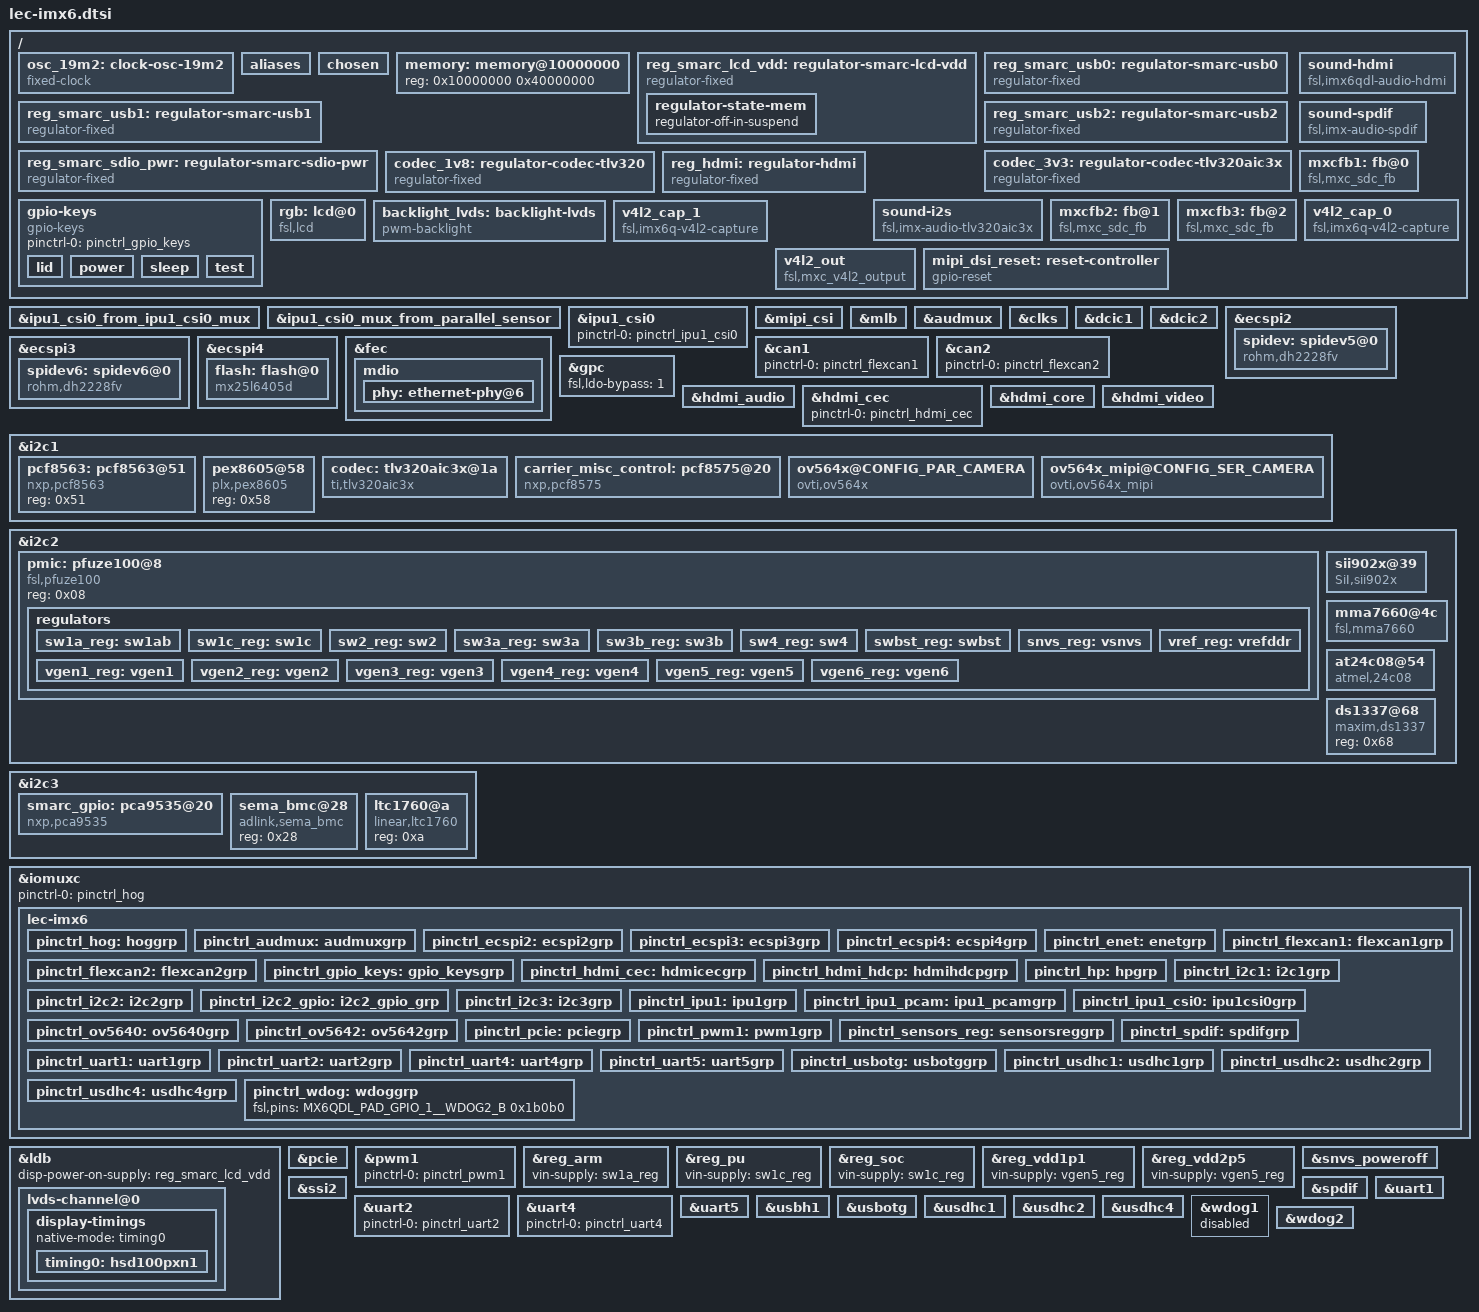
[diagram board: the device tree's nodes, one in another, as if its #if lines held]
// SPDX-License-Identifier: GPL-2.0+
//
// Copyright 2014-2016 LiPPERT ADLINK Technology GmbH
// Copyright 2012 Freescale Semiconductor, Inc.
// Copyright 2011 Linaro Ltd.

/* On-module multiplexer: 0 enables SMARC SPI0, !=0 enables I2S0 instead:
 * 1=TI TLV320AIC23 on LEC-Base R1 carrier, 2=Freescale SGTL5000 on LEC-Base R2 */
#define CONFIG_I2S_AUDIO       1
//#define CONFIG_I2S_AUDIO       2

/* The LEC-Base carrier doesn't include cameras, but allows connecting some. */
#define CONFIG_SER_CAMERA      3c /* I2C addr of serial camera, hex without "0x" */
//#define CONFIG_PAR_CAMERA    3c /* I2C addr of parallel camera */


/* Freescale defines 2 alternative DT nodes for the VPU: The one normally active
 * loads a driver called 'mxc_vpu'. The other, disabled one, would invoke a
 * different driver named 'coda'. None of Freescale's sample dts files enable it, 
 * but the code is there, appearently dormant, in imx6qdl.dtsi. 
*/
#define VPU_CODA       0

#include <dt-bindings/clock/imx6qdl-clock.h>
#include <dt-bindings/gpio/gpio.h>
#include <dt-bindings/input/input.h>

#define __0x(X) 0x##X  /* prefix hex digits with "0x" */
#define _0x(X) __0x(X)


/ {
	osc_19m2: clock-osc-19m2 {
        compatible = "fixed-clock";
        #clock-cells = <0>;
        clock-frequency = <19200000>;
        clock-output-names = "osc_19m2";
    };
	aliases {
		mxcfb0 = &mxcfb1;
		mxcfb1 = &mxcfb2;
		mxcfb2 = &mxcfb3;
	};

	chosen {
		/* U-Boot provides this via "console=..." in the 'params' variable. */
		//stdout-path = &uart1;
	};

	memory: memory@10000000 {
		device_type = "memory";
		reg = <0x10000000 0x40000000>;	/* dummy size, overwritten by U-Boot */
	};

	reg_smarc_lcd_vdd: regulator-smarc-lcd-vdd {
		compatible = "regulator-fixed";
		regulator-name = "smarc_lcd_vdd";
		gpio = <&gpio1 30 GPIO_ACTIVE_HIGH>; /* SMARC LCD_VDD_EN */
		enable-active-high;
		regulator-always-on; /* Freescale's fb/lcd/ldb drivers can't control a regulator yet :-( */
		regulator-state-mem { regulator-off-in-suspend; }; /* no effect? */
	};

	reg_smarc_usb0: regulator-smarc-usb0 {
		compatible = "regulator-fixed";
		regulator-name = "smarc_usb0";
		regulator-min-microvolt = <5000000>;
		regulator-max-microvolt = <5000000>;
		gpio = <&gpio1 27 GPIO_ACTIVE_HIGH>;	/* SMARC USB0_EN_OC# */
		enable-active-high;
	};

	reg_smarc_usb1: regulator-smarc-usb1 {
		compatible = "regulator-fixed";
		regulator-name = "smarc_usb1";
		regulator-min-microvolt = <5000000>;
		regulator-max-microvolt = <5000000>;
		gpio = <&gpio3 29 GPIO_ACTIVE_HIGH>;	/* SMARC USB1_EN_OC# */
		enable-active-high;
		/* Before enabling Vbus on the carrier power up the host phy's Vbus. */
		vin-supply = <&swbst_reg>;
	};

	reg_smarc_usb2: regulator-smarc-usb2 {
		compatible = "regulator-fixed";
		regulator-name = "smarc_usb2";
		regulator-min-microvolt = <5000000>;
		regulator-max-microvolt = <5000000>;
		gpio = <&gpio3 30 GPIO_ACTIVE_HIGH>; /* SMARC USB2_EN_OC# */
		enable-active-high;
		/* An on-module hub splits the i.MX6's usbh1 port into SMARC USB1 and 2.
		 * Devices on both are powered independently, via reg_smarc_usb1 and 2.
		 * But I've seen no way to model the hub in the device tree and usbh1
		 * takes only 1 "vbus-supply" line. So by declaring one as vin-supply
		 * for the other we trick usbh1 into enabling both. If someone needed to
		 * enable them separately they'd have to do it manually in user mode. */
		vin-supply = <&reg_smarc_usb1>;
	};

	reg_smarc_sdio_pwr: regulator-smarc-sdio-pwr {
		compatible = "regulator-fixed";
		regulator-name = "smarc_sdio_pwr";
		regulator-min-microvolt = <3300000>;
		regulator-max-microvolt = <3300000>;
		gpio = <&gpio4 11 GPIO_ACTIVE_HIGH>; /* SMARC SDIO_PWR_EN */
		enable-active-high;
		regulator-boot-on;
	};
#if CONFIG_I2S_AUDIO == 2
       /* Power supplies on the LEC-Base R2 carrier. They cannot be
        * controlled, but the SGTL5000 driver won't work without
        * regulator definitions. */
	reg_base_1v8: regulator-base-1v8 {
		compatible = "regulator-fixed";
		regulator-name = "base_1v8";
		regulator-min-microvolt = <1800000>;
		regulator-max-microvolt = <1800000>;
		regulator-boot-on;
		regulator-always-on;
	};

	reg_base_3v3: regulator-base-3v3 {
		compatible = "regulator-fixed";
		regulator-name = "base_3v3";
		regulator-min-microvolt = <3300000>;
		regulator-max-microvolt = <3300000>;
		regulator-boot-on;
		regulator-always-on;
	};
#endif
	codec_3v3: regulator-codec-tlv320aic3x {
                compatible = "regulator-fixed";
                regulator-name = "codec_3v3";
                startup-delay-us = <100>;
                enable-active-high;
        };

	codec_1v8: regulator-codec-tlv320 {
                compatible = "regulator-fixed";
                regulator-name = "codec_1v8";
                startup-delay-us = <100>;
                enable-active-high;
        };

    reg_hdmi: regulator-hdmi {
		compatible = "regulator-fixed";
		regulator-name = "hdmi-5v-supply";
		regulator-min-microvolt = <5000000>;
		regulator-max-microvolt = <5000000>;
		enable-active-high;
		hdmi-5v-supply = <&swbst_reg>;
    };

	gpio-keys {
		compatible = "gpio-keys";
		pinctrl-names = "default";
		pinctrl-0 = <&pinctrl_gpio_keys>;

		lid {
			label = "Lid switch";
			gpios = <&gpio1 7 GPIO_ACTIVE_LOW>; /* SMARC LID# */
			gpio-key,wakeup;
			linux,input-type = <5>; /* EV_SW */
			linux,code = <0>; /* SW_LID */
		};

		power {
			label = "Power button";
			gpios = <&gpio1 6 GPIO_ACTIVE_LOW>; /* SMARC POWER_BTN# */
			wakeup-source;
			linux,code = <KEY_POWER>;
		};

		sleep {
			label = "Sleep button";
			gpios = <&gpio2 7 GPIO_ACTIVE_LOW>; /* SMARC SLEEP# */
			wakeup-source;
			linux,code = <KEY_SLEEP>;
		};

		test {
			label = "Test button"; /* LEC-Base R2 carrier provides a button */
			gpios = <&gpio1 8 GPIO_ACTIVE_LOW>; /* SMARC TEST# */
			/* SMARC spec: "invoke module vendor specific test function(s)" */
			linux,code = <KEY_PROG1>; /* adapt to your needs */
		};
	};

#if CONFIG_I2S_AUDIO == 1
sound-i2s {     /* Audio codec on LEC-Base R1 carrier */
                compatible = "fsl,imx-audio-tlv320aic3x";
                model = "imx-tlv320aic3x";
                cpu-dai = <&ssi2>;
                mux-int-port = <2>;
                mux-ext-port = <3>;
                audio-codec = <&codec>;
                audio-routing =
                        "MIC3L", "Mic Jack",
                        "Mic Jack", "Mic Bias",
                        "Headphone Jack", "HPLOUT",
                        "Headphone Jack", "HPROUT";
        };
#elif CONFIG_I2S_AUDIO == 2
	sound-i2s {     /* Audio codec on LEC-Base R2 carrier */
		compatible = "fsl,imx-audio-sgtl5000";
		model = "imx-sgtl5000";
		ssi-controller = <&ssi2>;
		mux-int-port = <2>;
		mux-ext-port = <3>;
		audio-codec = <&codec>;
		asrc-controller = <&asrc>;
		audio-routing =
			"MIC_IN", "Mic Jack",
			"Mic Jack", "Mic Bias",
			"LINE_IN", "Line In Jack",
			//      "Headphone Jack", "HP_OUT",
			"Line Out Jack", "LINE_OUT";
	};
#endif
	sound-hdmi {
		compatible = "fsl,imx6qdl-audio-hdmi";
		model = "imx-audio-hdmi";
		hdmi-controller = <&hdmi_audio>;
	};

	sound-spdif {
		compatible = "fsl,imx-audio-spdif";
		model = "imx-spdif";
		spdif-controller = <&spdif>;
		spdif-in;
		spdif-out;
	};

	mxcfb1: fb@0 {	/* IPU1 DI1: /dev/fb0=HDMI, fb1=IPU1's overlay */
		compatible = "fsl,mxc_sdc_fb";
		disp_dev = "hdmi";
		interface_pix_fmt = "RGB24";
		mode_str ="1920x1080M@60";
		default_bpp = <32>;
		int_clk = <0>;
		late_init = <0>;
		status = "okay";
	};

	mxcfb2: fb@1 {	/* IPU1 DI0: /dev/fb2=parallel RGB */
		compatible = "fsl,mxc_sdc_fb";
		disp_dev = "lcd";
		interface_pix_fmt = "RGB24";
		mode_str ="CLAA-WVGA";
		default_bpp = <32>;
		int_clk = <0>;
		late_init = <0>;
		status = "okay";
	};

	mxcfb3: fb@2 {	/* IPU2 DI0: /dev/fb3=LVDS, fb4=IPU2's overlay
			* Solo/DL: IPU1, fb2 competing with par. RGB, no overlay */
		compatible = "fsl,mxc_sdc_fb";
		disp_dev = "ldb";
		interface_pix_fmt = "RGB24";
		default_bpp = <32>;
		int_clk = <0>;
		late_init = <0>;
		status = "okay";
	};

	rgb: lcd@0 {	/* parallel RGB (see fb above) */
		compatible = "fsl,lcd";
		ipu_id = <0>;
		disp_id = <0>;
		default_ifmt = "RGB24";
		pinctrl-names = "default";
		pinctrl-0 = <&pinctrl_ipu1>;
		disp-power-on-supply = <&reg_smarc_lcd_vdd>; /* unsupported by driver */
		status = "okay";
	};

	backlight_lvds: backlight-lvds {
		compatible = "pwm-backlight";
		pwms = <&pwm1 0 5000000 0>;
		brightness-levels = <0 4 8 16 32 64 128 255>;
		default-brightness-level = <6>;
		enable-gpios = <&gpio6 10 GPIO_ACTIVE_HIGH>; /* SMARC LCD_BKLT_EN */
		status = "okay";
	};

	/* The LEC-Base carriers don't have any LEDs, just show how it's done. */
	//leds {
	//	compatible = "gpio-leds";
	//
	//	example-led {
	//		gpios = <&smarc_gpio 5 GPIO_ACTIVE_LOW>; /* SMARC GPIO5/PWM_OUT */
	//		linux,default-trigger = "mmc1"; /* more triggers in menuconfig */
	//	};
	//};

#ifdef CONFIG_PAR_CAMERA
	v4l2_cap_0 {
		compatible = "fsl,imx6q-v4l2-capture";
		ipu_id = <0>;
		csi_id = <0>;
		mclk_source = <0>;
		status = "okay";
	};
#endif

#ifdef CONFIG_SER_CAMERA
	v4l2_cap_1 {
		compatible = "fsl,imx6q-v4l2-capture";
		ipu_id = <0>;
		csi_id = <1>;
		mclk_source = <0>;
		status = "okay";
	};
#endif

	v4l2_out {
		compatible = "fsl,mxc_v4l2_output";
		status = "okay";
	};

	mipi_dsi_reset: reset-controller {
		compatible = "gpio-reset";
		reset-gpios = <&gpio6 11 GPIO_ACTIVE_LOW>;
		reset-delay-us = <50>;
		#reset-cells = <0>;
		status = "okay";
	};
};

&ipu1_csi0_from_ipu1_csi0_mux {
	bus-width = <8>;
	data-shift = <12>; /* Lines 19:12 used */
	hsync-active = <1>;
	vsync-active = <1>;
};

&ipu1_csi0_mux_from_parallel_sensor {
#if 0
	remote-endpoint = <&ov5642_to_ipu1_csi0_mux>;
#endif
};

&ipu1_csi0 {
	pinctrl-names = "default";
	pinctrl-0 = <&pinctrl_ipu1_csi0>;
};

#ifdef CONFIG_SER_CAMERA
&mipi_csi {
	ipu_id = <0>;
	csi_id = <1>;
	v_channel = <0>;
	lanes = <2>;
	status = "okay";
};
#endif

&mlb {		/* SMARC AFB_DIFF1-3 */
	/* Driver doesn't seem to support differential (6-pin) mode. */
	//status = "okay";
};

#if VPU_CODA
&vpu {
	status = "okay";
};
&vpu_fsl {
	status = "disabled";
};
#endif

#if CONFIG_I2S_AUDIO
&audmux {	/* SMARC I2S0 (instead of SPI0) */
	pinctrl-names = "default";
	pinctrl-0 = <&pinctrl_audmux>;
	pinctrl-assert-gpios = <&gpio1 3 GPIO_ACTIVE_HIGH>; /* AEN# */
	status = "okay";
};
#endif

&clks {
	assigned-clocks = <&clks IMX6QDL_CLK_LDB_DI0_SEL>,	/*LVDS*/
			  <&clks IMX6QDL_CLK_LDB_DI1_SEL>;	/*unused*/
	assigned-clock-parents = <&clks IMX6QDL_CLK_PLL2_PFD0_352M>,
				 <&clks IMX6QDL_CLK_PLL2_PFD0_352M>;
};

&dcic1 {
	dcic_id = <0>;
	dcic_mux = "dcic-hdmi";
	status = "okay";
};

&dcic2 {
	dcic_id = <1>;
	dcic_mux = "dcic-lvds0";
	status = "okay";
};

#if 0
#if !CONFIG_I2S_AUDIO
&ecspi1 {	/* SMARC SPI0 (instead of I2S0) */
	fsl,spi-num-chipselects = <2>;
	cs-gpios = <&gpio5 25 GPIO_ACTIVE_LOW>, /* SMARC CS0 */
		   <&gpio3 24 GPIO_ACTIVE_LOW>; /* SMARC CS1 */
	pinctrl-names = "default";
	pinctrl-0 = <&pinctrl_ecspi1>;
	pinctrl-assert-gpios = <&gpio1 3 GPIO_ACTIVE_LOW>; /* AEN# */
	status = "okay";

	tsc2046@0 {             /* Touch screen controller on LEC-Base R1 carrier */
		compatible = "ti,tsc2046";
		reg = <0>;
		vcc-supply = <&reg_smarc_lcd_vdd>;
		spi-max-frequency = <2500000>;
		interrupt-parent = <&smarc_gpio>;
		interrupts = <10 IRQ_TYPE_EDGE_FALLING>; /* SMARC GPIO10 */
		pendown-gpio = <&smarc_gpio 10 GPIO_ACTIVE_LOW>;
		ti,vref-mv = /bits/ 16 <3300>;
	};
};
#endif
#endif

&ecspi2 {	/* SMARC SPI1 */
	fsl,spi-num-chipselects = <2>;
	cs-gpios = <&gpio2 27 GPIO_ACTIVE_LOW>, /* SMARC CS0 */
		<&gpio2 26 GPIO_ACTIVE_LOW>; /* SMARC CS1 */
	pinctrl-names = "default";
	pinctrl-0 = <&pinctrl_ecspi2>;
	status = "okay";

	spidev:spidev5@0 {
		status = "okay";
		compatible = "rohm,dh2228fv";
		spi-max-frequency = <2500000>;
		reg = <0>;
	};
};

&ecspi3 {      /* SMARC SPI2 */
 	fsl,spi-num-chipselects = <1>;
	cs-gpios = <&gpio3 25 GPIO_ACTIVE_LOW>; /* SMARC CS0 */
	pinctrl-names = "default";
	pinctrl-0 = <&pinctrl_ecspi3>;
	status = "okay";

	spidev6:spidev6@0 {
		status = "okay";
		compatible = "rohm,dh2228fv";
		spi-max-frequency = <2500000>;
		reg = <0>;
	};
};

&ecspi4 {	/* on-module U-Boot SPI */
	fsl,spi-num-chipselects = <2>;
	cs-gpios = <&gpio4 24 GPIO_ACTIVE_LOW>, /* SMARC CS0 */
		   <&gpio4 25 GPIO_ACTIVE_LOW>;
	pinctrl-names = "default";
	pinctrl-0 = <&pinctrl_ecspi4>;
	status = "okay";

	flash: flash@0 {
		#address-cells = <1>;
		#size-cells = <1>;
		#compatible = "spansion,m25p80", "jedec,spi-nor";
		compatible = "mx25l6405d";
		spi-max-frequency = <40000000>; /* slowest we used was SST25VF032B; i.MX6 provides 60MHz max */
 		reg = <0>;
		spi-cpol;
		spi-cpha;
	};
};

&fec {
	pinctrl-names = "default";
	pinctrl-0 = <&pinctrl_enet>;
	phy-mode = "rgmii-id";
	phy-handle = <&phy>;
	/* Can't power off phy because sw2_reg is permanently needed. We could
	 * turn off i.MX6's NVCC_RGMII (I/O voltage) only, but that's risky when
	 * the phy remains powered. */
	//phy-supply = <&vgen1_reg>;
	fsl,magic-packet;
	status = "okay";

	mdio {
		#address-cells = <1>;
		#size-cells = <0>;

		phy: ethernet-phy@6 {
			reg = <6>;
			qca,clk-out-frequency = <125000000>;
			/* Longer RGMII traces and a serial resistor in TXC: the
			 * GTX_CLK delay must be 1.3 ns instead of 2.4 ns (default). */
			tx-internal-delay-ps = <1300>;
			reset-gpios = <&gpio1 25 GPIO_ACTIVE_LOW>;
			reset-assert-us = <10000>;
		};
	};
};

&can1 {
	pinctrl-names = "default";
	pinctrl-0 = <&pinctrl_flexcan1>;
	//trx-nerr-gpio = <&smarc_gpio 8 GPIO_ACTIVE_LOW>; /* SMARC GPIO8/CAN0_ERR#, unused on LEC-Base carrier */
	//trx-stby-gpio = <&carrier_misc_control 1 GPIO_ACTIVE_HIGH>; /* CAN1_STB, solder jumper not populated */
	status = "okay";
};

&can2 {
	pinctrl-names = "default";
	pinctrl-0 = <&pinctrl_flexcan2>;
	//trx-nerr-gpio = <&smarc_gpio 9 GPIO_ACTIVE_LOW>; /* SMARC GPIO9/CAN1_ERR#, unused on LEC-Base carrier */
	//trx-stby-gpio = <&carrier_misc_control 2 GPIO_ACTIVE_HIGH>; /* CAN2_STB, solder jumper not populated */
	status = "okay";
};

&gpc {
	fsl,ldo-bypass = <1>;
};

&hdmi_audio {
	status = "okay";
};

&hdmi_cec {
	pinctrl-names = "default";
	pinctrl-0 = <&pinctrl_hdmi_cec>;
	status = "okay";
};

&hdmi_core {	/* HDMI (see fb above) */
	ipu_id = <0>;
	disp_id = <1>;
	status = "okay";
};

&hdmi_video {
	fsl,phy_reg_vlev = <0x294>;
	fsl,phy_reg_cksymtx = <0x800d>;
	pinctrl-names = "default";
	pinctrl-0 = <&pinctrl_hdmi_hdcp>;
	fsl,hdcp; /* also means we use the dedicated DDC function */
	fsl,phy_reg_vlev = <0x03f4>;
	fsl,phy_reg_cksymtx = <0x800f>;
	/* In the list of predefined video modes include any provided by the
	 * monitor's EDID data instead of only a few found in mxc_edid.c:
	 * mxc_cea_mode[].
	 * With this enabled we got an HDMI TV's native resolution instead of a
	 * blurry interpolated image. On the downside HDMI audio sounded
	 * distorted and parallel RGB, which shared the same i.MX6 IPU, then
	 * failed to work properly. We don't know if this is an i.MX6 hardware
	 * limitation or a bug in Freescale's driver. Regardless of this option
	 * fbset can set any timing manually. */
	//fsl,allow-all-modes;
	HDMI-supply = <&reg_hdmi>;
	status = "okay";
};

&i2c1 {		/* RTC, optional PCIe switch, SMARC I2C_CAM */
	clock-frequency = <100000>; /* 66 MHz / 768 = 86 kHz */
	pinctrl-names = "default";
	pinctrl-0 = <&pinctrl_i2c1>;
	status = "okay";

	pcf8563: pcf8563@51 {                           /* Real Time Clock */
		compatible = "nxp,pcf8563";
		reg = <0x51>;
	};

	pex8605@58 {				/* optional PCIe switch */
		compatible = "plx,pex8605";	/* guessing, no driver found */
		reg = <0x58>;
	};
#if CONFIG_I2S_AUDIO == 1
codec: tlv320aic3x@1a {
                #sound-dai-cells = <0>;
                compatible = "ti,tlv320aic3x";
                reg = <0x1a>;
                clocks = <&osc_19m2>;
                clock-names = "mclk";

                AVDD-supply = <&codec_3v3>;
                IOVDD-supply = <&codec_1v8>;
                DRVDD-supply = <&codec_3v3>;
                DVDD-supply = <&codec_1v8>;

                ai3x-micbias-vg = <1>;
                ai3x-ocmv = <3>;
                status = "okay";
        };
#endif

#if CONFIG_I2S_AUDIO == 2
	codec: sgtl5000@0a {            /* Audio codec on LEC-Base R2 carrier */
		compatible = "fsl,sgtl5000";
		reg = <0x0a>;
		clocks = <&clks IMX6QDL_CLK_CKO>; /* SMARC AUDIO_MCK, actually unused on carrier */
		VDDA-supply = <&reg_base_3v3>;
		VDDIO-supply = <&reg_base_1v8>;
		VDDD-supply = <&reg_base_1v8>;
		micbias-resistor-k-ohms = <4>;
		micbias-voltage-m-volts = <1250>;
	};
#endif

       carrier_misc_control: pcf8575@20 {      /* GPIO expander on LEC-Base R1 carrier */
               compatible = "nxp,pcf8575";
               reg = <0x20>;
               gpio-controller;
               #gpio-cells = <2>;
               /* 0: HUB1_RESET         8: 3G1_DISABLE#
                * 1: CAN1_STB (NC)      9: 3G1_DOWN#
                * 2: CAN2_STB (NC)     10: 3G2_DISABLE#
                * 3: LCD_RESET# (NC)   11: 3G2_DOWN#
                * 4: SUP_RESET# (NC)   12: HDMI_RESET#
                * 5: LVDS_VDD_EN       13: 3G_PW_EN
                * 6: CAM_PW_EN (NC)    14: PCAM_LE#
                * 7: GPS_VDD_EN        15: HUB2_RESET */
               lines-initial-states = <0xc001>; /* bitmask: 0=high(!)/input, 1=pulled low */
       };

#ifdef CONFIG_PAR_CAMERA
	ov564x@CONFIG_PAR_CAMERA {	/* Parallel camera connected to carrier */
		compatible = "ovti,ov564x";
		reg = <_0x(CONFIG_PAR_CAMERA)>;
		pinctrl-names = "default";
		pinctrl-0 = <&pinctrl_ipu1_pcam>;
		clocks = <&clks IMX6QDL_CLK_CKO>;
		clock-names = "csi_mclk";
		pwn-gpios = <&gpio6 14 GPIO_ACTIVE_HIGH>; /* SMARC GPIO1/CAM1_PWR# */
		rst-gpios = <&gpio6 16 GPIO_ACTIVE_LOW>;  /* SMARC GPIO3/CAM1_RST# */
		csi_id = <0>; /* but on SMARC CSI1_...! */
		mclk = <24000000>;
		mclk_source = <0>;
	};
#endif

#ifdef CONFIG_SER_CAMERA
	ov564x_mipi@CONFIG_SER_CAMERA {         /* Serial camera connected to carrier */
		compatible = "ovti,ov564x_mipi";
		reg = <_0x(CONFIG_SER_CAMERA)>;
		clocks = <&clks IMX6QDL_CLK_CKO>;
		clock-names = "csi_mclk";
		pwn-gpios = <&gpio6 11 GPIO_ACTIVE_HIGH>; /* SMARC GPIO0/CAM0_PWR# */
		rst-gpios = <&gpio6 15 GPIO_ACTIVE_LOW>;  /* SMARC GPIO2/CAM0_RST# */
		csi_id = <1>; /* but on SMARC CSI0_...! */
		mclk = <24000000>;
		mclk_source = <0>;
	};
#endif
};

&i2c2 {		/* PFUZE100 PMIC, SMARC I2C_LCD, SMARC I2C_GP */
	clock-frequency = <100000>;
	pinctrl-names = "default", "gpio";
	pinctrl-0 = <&pinctrl_i2c2>;
	pinctrl-1 = <&pinctrl_i2c2_gpio>;
	scl-gpios = <&gpio4 12 GPIO_ACTIVE_HIGH>;
	sda-gpios = <&gpio4 13 GPIO_ACTIVE_HIGH>;
	status = "okay";

	pmic: pfuze100@8 {
		compatible = "fsl,pfuze100";
		reg = <0x08>;

		regulators {
			sw1a_reg: sw1ab {	/* VDDCORE: VDDARM */
				regulator-min-microvolt = <300000>;
				regulator-max-microvolt = <1875000>;
				regulator-boot-on;
				regulator-always-on;
				regulator-ramp-delay = <6250>;
			};

			sw1c_reg: sw1c {	/* VDDSOC */
				regulator-min-microvolt = <300000>;
				regulator-max-microvolt = <1875000>;
				regulator-boot-on;
				regulator-always-on;
				regulator-ramp-delay = <6250>;
			};

			sw2_reg: sw2 {	/* GEN_3V3: NVCC_ENET (eth mac), eth phy, USB hub, eMMC, lots of misc stuff */
				regulator-min-microvolt = <800000>;
				regulator-max-microvolt = <3300000>;
				regulator-boot-on;
				regulator-always-on;
				regulator-ramp-delay = <6250>;
			};

			sw3a_reg: sw3a {	/* DDR_1V5 */
				regulator-min-microvolt = <400000>;
				regulator-max-microvolt = <1975000>;
				regulator-boot-on;
				regulator-always-on;
			};

			sw3b_reg: sw3b {	/* dito */
				regulator-min-microvolt = <400000>;
				regulator-max-microvolt = <1975000>;
				regulator-boot-on;
				regulator-always-on;
			};

			sw4_reg: sw4 {	/* PMIC_1V8: VDD_IO and lots of stuff everywhere */
				regulator-min-microvolt = <800000>;
				regulator-max-microvolt = <3300000>;
				regulator-always-on;
			};

			swbst_reg: swbst {	/* PMIC_5V: USB h1 Vbus (for phy, rest is provided by carrier) */
				regulator-min-microvolt = <5000000>;
				regulator-max-microvolt = <5150000>;
			};

			snvs_reg: vsnvs {	/* PMIC_VSNVS (3V) */
				regulator-min-microvolt = <1000000>;
				regulator-max-microvolt = <3000000>;
				regulator-boot-on;
				regulator-always-on;
			};

			vref_reg: vrefddr {	/* DDR_VREF */
				regulator-boot-on;
				regulator-always-on;
			};

			vgen1_reg: vgen1 {	/* VGEN1_1V5: NVCC_RGMII (i.MX6's I/O to external eth phy) */
				regulator-min-microvolt = <800000>;
				regulator-max-microvolt = <1550000>;
				regulator-boot-on;
				regulator-always-on; /* we can't power off phy itself */
			};

			vgen2_reg: vgen2 {	/* unused */
				regulator-min-microvolt = <800000>;
				regulator-max-microvolt = <1550000>;
			};

			vgen3_reg: vgen3 {	/* VGEN3_2V5: NVCC_LVDS (LVDS, DRAM, RGMII), SPI/I2S mux */
				regulator-min-microvolt = <1800000>;
				regulator-max-microvolt = <3300000>;
				regulator-boot-on;
				regulator-always-on; /* despite its name, NVCC_LVDS also supplies DRAM_IO */
			};

			vgen4_reg: vgen4 {	/* VDDHIGH_IN (2.8V): SATA, PCIe, HDMI, MIPI, LVDS, USB, PLLs */
				regulator-min-microvolt = <1800000>;
				regulator-max-microvolt = <3300000>;
				regulator-boot-on;
				regulator-always-on;
			};

			vgen5_reg: vgen5 {	/* dito, but unused per default (since LEC-iMX6 rev A4) */
				regulator-min-microvolt = <1800000>;
				regulator-max-microvolt = <3300000>;
				regulator-boot-on;
				//regulator-always-on;	/* solder jumper */
			};

			vgen6_reg: vgen6 {	/* VGEN6_3V3: PCIe switch, PCIe reset */
				regulator-min-microvolt = <1800000>;
				regulator-max-microvolt = <3300000>;
				regulator-boot-on;
				/* no driver for PCIe switch, no regulator in i.MX6 driver and we couldn't
				   power down carrier devices or host, only PCIe switch in between */
				regulator-always-on;
			};
		};
	};

#if CONFIG_I2S_AUDIO == 2
	codec: sgtl5000@0a {            /* Audio codec on LEC-Base R2 carrier */
		compatible = "fsl,sgtl5000";
		reg = <0x0a>;
		clocks = <&clks IMX6QDL_CLK_CKO>; /* SMARC AUDIO_MCK, actually unused on carrier */
		VDDA-supply = <&reg_base_3v3>;
		VDDIO-supply = <&reg_base_1v8>;
		VDDD-supply = <&reg_base_1v8>;
		micbias-resistor-k-ohms = <4>;
		micbias-voltage-m-volts = <1250>;
	};
#endif
	/* Current driver depends on MXS framebuffer not present on i.MX6Q/D/DL/S.
	 * Also assuming LEC-Base R1 JP3=1-2, JP15=2-3. */
	sii902x@39 {                    /* HDMI transmitter on LEC-Base R1 carrier */
		compatible = "SiI,sii902x";
		reg = <0x39>;
		interrupt-parent = <&smarc_gpio>;
		interrupts = <4 IRQ_TYPE_EDGE_FALLING>; /* SMARC GPIO4/HDA_RST# */
		mode_str = "1280x720M@60";
		bits-per-pixel = <32>;
	};

	mma7660@4c {                    /* Accelerometer on LEC-Base R1 carrier */
		compatible = "fsl,mma7660"; /* guessing, no driver mainlined */
		reg = <0x4c>;
		interrupt-parent = <&smarc_gpio>;
		interrupts = <11 IRQ_TYPE_LEVEL_LOW>; /* SMARC GPIO11 */
	};

	at24c08@54 {                    /* 1KB EEPROM on LEC-Base R1 carrier */
		compatible = "atmel,24c08";
		reg = <0x54>;
		pagesize = <16>;
	};

	/* Driver disabled in defconfig, we have an on-module RTC already. */
	ds1337@68 {                     /* RTC on LEC-Base R1 carrier */
		compatible = "maxim,ds1337";
		reg = <0x68>;
	};
};

&i2c3 {		/* GPIO expander, SEMA BMC, SMARC I2C_PM */
	clock-frequency = <100000>;
	pinctrl-names = "default";
	pinctrl-0 = <&pinctrl_i2c3>;
	status = "okay";

	smarc_gpio: pca9535@20 {	/* GPIO expander */
		/* GPIOs 4-6, 8-11 map directly to the SMARC connector's GPIOx.
		 * GPIOs 0-3, 7 are unused unless a solder jumper is changed, per default
		 * SMARC GPIO0-3,7 are provided by the i.MX6 (CAM0/1_PWR/RST#,PCAM_FLD). */
		compatible = "nxp,pca9535";
		reg = <0x20>;
		interrupt-parent = <&gpio1>;
		interrupts = <29 IRQ_TYPE_LEVEL_LOW>; /* GPIO_INT_B */
		gpio-controller;
		#gpio-cells = <2>;
		interrupt-controller;
		#interrupt-cells = <2>;
	};

	sema_bmc@28 {		/* SEMA Board Management Controller */
		compatible = "adlink,sema_bmc"; /* no driver needed */
		reg = <0x28>;
	};

	ltc1760@a {		/* Battery charger on LEC-Base R1 carrier */
		compatible = "linear,ltc1760"; /* guessing, no driver found */
		reg = <0xa>;
	};
};

&iomuxc {
	pinctrl-names = "default";
	pinctrl-0 = <&pinctrl_hog>;

	lec-imx6 {
		pinctrl_hog: hoggrp {
			fsl,pins = <
				/* Native pad functions */
				MX6QDL_PAD_GPIO_0__CCM_CLKO1    0x130b0
				/* Pads used for GPIOs */
				MX6QDL_PAD_GPIO_3__GPIO1_IO03   0x80000000 /* AEN# (mux: 0=SPI0, 1=I2S0) */
				MX6QDL_PAD_ENET_TXD1__GPIO1_IO29 0x80000000 /* GPIO_INT_B */
				MX6QDL_PAD_ENET_TXD0__GPIO1_IO30 0x80000000 /* SMARC LCD_VDD_EN */
				MX6QDL_PAD_ENET_RXD0__GPIO1_IO27 0x1a8b0 /* SMARC USB0_EN_OC# (open-drain) */
				MX6QDL_PAD_EIM_D29__GPIO3_IO29	0x1a8b0 /* SMARC USB1_EN_OC# (open-drain) */
				MX6QDL_PAD_EIM_D30__GPIO3_IO30	0x1a8b0 /* SMARC USB2_EN_OC# (open-drain) */
				MX6QDL_PAD_KEY_ROW2__GPIO4_IO11	0x80000000 /* SMARC SDIO_PWR_EN */
				MX6QDL_PAD_NANDF_CS0__GPIO6_IO11 0x80000000 /* SMARC GPIO0/CAM0_PWR# */
				MX6QDL_PAD_NANDF_CS1__GPIO6_IO14 0x80000000 /* SMARC GPIO1/CAM1_PWR# */
				MX6QDL_PAD_NANDF_CS2__GPIO6_IO15 0x80000000 /* SMARC GPIO2/CAM0_RST# */
				MX6QDL_PAD_NANDF_CS3__GPIO6_IO16 0x80000000 /* SMARC GPIO3/CAM1_RST# */
				MX6QDL_PAD_NANDF_CLE__GPIO6_IO07 0x80000000 /* SMARC GPIO7/PCAM_FLD */
			>;
		};

#if CONFIG_I2S_AUDIO
		pinctrl_audmux: audmuxgrp {	/* SMARC I2S0 (instead of SPI0) */
			fsl,pins = <
				MX6QDL_PAD_CSI0_DAT7__AUD3_RXD		0x130b0
				MX6QDL_PAD_CSI0_DAT4__AUD3_TXC		0x130b0
				MX6QDL_PAD_CSI0_DAT5__AUD3_TXD		0x110b0
				MX6QDL_PAD_CSI0_DAT6__AUD3_TXFS		0x130b0
			>;
		};
#else
		pinctrl_ecspi1: ecspi1grp {
			fsl,pins = <    /* SMARC SPI0 (instead of I2S0) */
				MX6QDL_PAD_CSI0_DAT6__ECSPI1_MISO       0x100b1
				MX6QDL_PAD_CSI0_DAT5__ECSPI1_MOSI       0x100b1
				MX6QDL_PAD_CSI0_DAT4__ECSPI1_SCLK       0x100b1
				MX6QDL_PAD_CSI0_DAT7__GPIO5_IO25        0x1b0b0 /* SMARC CS0 */
				MX6QDL_PAD_EIM_D24__GPIO3_IO24          0x1b0b0 /* SMARC CS1 */
			>;
		};
#endif

		pinctrl_ecspi2: ecspi2grp {
			fsl,pins = <	/* SMARC SPI1 */
				MX6QDL_PAD_EIM_OE__ECSPI2_MISO          0x100b1
				MX6QDL_PAD_EIM_CS1__ECSPI2_MOSI         0x100b1
				MX6QDL_PAD_EIM_CS0__ECSPI2_SCLK         0x100b1
				MX6QDL_PAD_EIM_RW__GPIO2_IO26           0x1b0b0 /* SMARC CS1 */
				MX6QDL_PAD_EIM_LBA__GPIO2_IO27          0x1b0b0 /* SMARC CS0 */
			>;
		};

		pinctrl_ecspi3: ecspi3grp {
			fsl,pins = <    /* SMARC SPI2 */
				MX6QDL_PAD_DISP0_DAT2__ECSPI3_MISO      0x100b1
				MX6QDL_PAD_DISP0_DAT1__ECSPI3_MOSI      0x100b1
				MX6QDL_PAD_DISP0_DAT0__ECSPI3_SCLK      0x100b1
				MX6QDL_PAD_DISP0_DAT3__GPIO4_IO24       0x1b0b0 /* CS0 */
				MX6QDL_PAD_DISP0_DAT4__GPIO4_IO25       0x1b0b0 /* CS1 */
                        >;
                };


		pinctrl_ecspi4: ecspi4grp {
			fsl,pins = <	/* on-module U-Boot SPI */
				MX6QDL_PAD_EIM_D22__ECSPI4_MISO         0x100b1
				MX6QDL_PAD_EIM_D28__ECSPI4_MOSI         0x100b1
				MX6QDL_PAD_EIM_D21__ECSPI4_SCLK         0x100b1
				MX6QDL_PAD_EIM_D25__GPIO3_IO25          0x1b0b0 /* CS3 */
			>;
		};

		pinctrl_enet: enetgrp {
			fsl,pins = <
				MX6QDL_PAD_ENET_MDIO__ENET_MDIO		0x1b0b0
				MX6QDL_PAD_ENET_MDC__ENET_MDC		0x1b0b0
				MX6QDL_PAD_RGMII_TXC__RGMII_TXC		0x1b0b8	/* serial resistor added */
				MX6QDL_PAD_RGMII_TD0__RGMII_TD0		0x1b030
				MX6QDL_PAD_RGMII_TD1__RGMII_TD1		0x1b030
				MX6QDL_PAD_RGMII_TD2__RGMII_TD2		0x1b030
				MX6QDL_PAD_RGMII_TD3__RGMII_TD3		0x1b030
				MX6QDL_PAD_RGMII_TX_CTL__RGMII_TX_CTL	0x1b030
				MX6QDL_PAD_ENET_REF_CLK__ENET_TX_CLK	0x1b0b0
				MX6QDL_PAD_RGMII_RXC__RGMII_RXC		0x1b030
				MX6QDL_PAD_RGMII_RD0__RGMII_RD0		0x1b030
				MX6QDL_PAD_RGMII_RD1__RGMII_RD1		0x1b030
				MX6QDL_PAD_RGMII_RD2__RGMII_RD2		0x1b030
				MX6QDL_PAD_RGMII_RD3__RGMII_RD3		0x1b030
				MX6QDL_PAD_RGMII_RX_CTL__RGMII_RX_CTL	0x1b030
				MX6QDL_PAD_ENET_CRS_DV__GPIO1_IO25	0x80000000 /* RGMII_nRST */
				//MX6QDL_PAD_ENET_RXD1__GPIO1_IO26	0x80000000 /* RGMII_INT */
				/* For the workaround improving network latency described in i.MX6
				 * erratum 6687 disable the power button, re-mux as follows and
				 * add "interrupts-extended" as in imx6q-sabresd-enetirq.dts. */
				//MX6QDL_PAD_GPIO_6__ENET_IRQ		0x000b1
			>;
		};

		pinctrl_flexcan1: flexcan1grp {
			fsl,pins = <    /* SMARC CAN0 */
				MX6QDL_PAD_SD3_CMD__FLEXCAN1_TX         0x17059
				MX6QDL_PAD_SD3_CLK__FLEXCAN1_RX         0x17059
			>;
		};

		pinctrl_flexcan2: flexcan2grp {
			fsl,pins = <    /* SMARC CAN1 */
				MX6QDL_PAD_SD3_DAT0__FLEXCAN2_TX        0x17059
				MX6QDL_PAD_SD3_DAT1__FLEXCAN2_RX        0x17059
			>;
		};

		pinctrl_gpio_keys: gpio_keysgrp {
			fsl,pins = <
				MX6QDL_PAD_GPIO_7__GPIO1_IO07           0x1b0b0 /* SMARC LID# */
				MX6QDL_PAD_GPIO_6__GPIO1_IO06           0x1b0b0 /* SMARC POWER_BTN# */
				MX6QDL_PAD_NANDF_D7__GPIO2_IO07         0x1b0b0 /* SMARC SLEEP# */
				MX6QDL_PAD_GPIO_8__GPIO1_IO08           0x1b0b0 /* SMARC TEST# */
			>;
		};

		pinctrl_hdmi_cec: hdmicecgrp {
			fsl,pins = <
				MX6QDL_PAD_EIM_A25__HDMI_TX_CEC_LINE	0x108b0
			>;
		};

		pinctrl_hdmi_hdcp: hdmihdcpgrp {
			fsl,pins = <
				MX6QDL_PAD_KEY_COL3__HDMI_TX_DDC_SCL 0x4001b8b1
				MX6QDL_PAD_KEY_ROW3__HDMI_TX_DDC_SDA 0x4001b8b1
			>;
		};

		pinctrl_hp: hpgrp {
			fsl,pins = <
				MX6QDL_PAD_SD3_RST__GPIO7_IO08          0x1b0b0
				MX6QDL_PAD_GPIO_9__GPIO1_IO09           0x1b0b0
			>;
		};

		pinctrl_i2c1: i2c1grp {
			fsl,pins = <
				MX6QDL_PAD_CSI0_DAT8__I2C1_SDA		0x4001b8b1
				MX6QDL_PAD_CSI0_DAT9__I2C1_SCL		0x4001b8b1
			>;
		};

		pinctrl_i2c2: i2c2grp {
			fsl,pins = <
				MX6QDL_PAD_EIM_EB2__I2C2_SCL		0x4001b8b1
				MX6QDL_PAD_EIM_D16__I2C2_SDA		0x4001b8b1
			>;
		};

		pinctrl_i2c2_gpio: i2c2_gpio_grp {
			fsl,pins = <
				MX6QDL_PAD_KEY_COL3__GPIO4_IO12         0x1b0b0
				MX6QDL_PAD_KEY_ROW3__GPIO4_IO13         0x1b0b0
			>;
		};

		pinctrl_i2c3: i2c3grp {
			fsl,pins = <
				MX6QDL_PAD_EIM_D17__I2C3_SCL		0x4001b8b1
				MX6QDL_PAD_EIM_D18__I2C3_SDA		0x4001b8b1
			>;
		};

		pinctrl_ipu1: ipu1grp {
			fsl,pins = <
				MX6QDL_PAD_DI0_DISP_CLK__IPU1_DI0_DISP_CLK 0xf1
				MX6QDL_PAD_DI0_PIN15__IPU1_DI0_PIN15       0xf1
				MX6QDL_PAD_DI0_PIN2__IPU1_DI0_PIN02        0xf1
				MX6QDL_PAD_DI0_PIN3__IPU1_DI0_PIN03        0xf1
				MX6QDL_PAD_DI0_PIN4__IPU1_DI0_PIN04        0x80000000
				MX6QDL_PAD_DISP0_DAT5__IPU1_DISP0_DATA05   0xf1
				MX6QDL_PAD_DISP0_DAT6__IPU1_DISP0_DATA06   0xf1
				MX6QDL_PAD_DISP0_DAT7__IPU1_DISP0_DATA07   0xf1
				MX6QDL_PAD_DISP0_DAT8__IPU1_DISP0_DATA08   0xf1
				MX6QDL_PAD_DISP0_DAT9__IPU1_DISP0_DATA09   0xf1
				MX6QDL_PAD_DISP0_DAT10__IPU1_DISP0_DATA10  0xf1
				MX6QDL_PAD_DISP0_DAT11__IPU1_DISP0_DATA11  0xf1
				MX6QDL_PAD_DISP0_DAT12__IPU1_DISP0_DATA12  0xf1
				MX6QDL_PAD_DISP0_DAT13__IPU1_DISP0_DATA13  0xf1
				MX6QDL_PAD_DISP0_DAT14__IPU1_DISP0_DATA14  0xf1
				MX6QDL_PAD_DISP0_DAT15__IPU1_DISP0_DATA15  0xf1
				MX6QDL_PAD_DISP0_DAT16__IPU1_DISP0_DATA16  0xf1
				MX6QDL_PAD_DISP0_DAT17__IPU1_DISP0_DATA17  0xf1
				MX6QDL_PAD_DISP0_DAT18__IPU1_DISP0_DATA18  0xf1
				MX6QDL_PAD_DISP0_DAT19__IPU1_DISP0_DATA19  0xf1
				MX6QDL_PAD_DISP0_DAT20__IPU1_DISP0_DATA20  0xf1
				MX6QDL_PAD_DISP0_DAT21__IPU1_DISP0_DATA21  0xf1
				MX6QDL_PAD_DISP0_DAT22__IPU1_DISP0_DATA22  0xf1
				MX6QDL_PAD_DISP0_DAT23__IPU1_DISP0_DATA23  0xf1
			>;
		};

#ifdef CONFIG_PAR_CAMERA
		pinctrl_ipu1_pcam: ipu1_pcamgrp {
			fsl,pins = <	/* SMARC PCAM */
				MX6QDL_PAD_CSI0_DAT10__IPU1_CSI0_DATA10    0x80000000
				MX6QDL_PAD_CSI0_DAT11__IPU1_CSI0_DATA11    0x80000000
				MX6QDL_PAD_CSI0_DAT12__IPU1_CSI0_DATA12    0x80000000
				MX6QDL_PAD_CSI0_DAT13__IPU1_CSI0_DATA13    0x80000000
				MX6QDL_PAD_CSI0_DAT14__IPU1_CSI0_DATA14    0x80000000
				MX6QDL_PAD_CSI0_DAT15__IPU1_CSI0_DATA15    0x80000000
				MX6QDL_PAD_CSI0_DAT16__IPU1_CSI0_DATA16    0x80000000
				MX6QDL_PAD_CSI0_DAT17__IPU1_CSI0_DATA17    0x80000000
				MX6QDL_PAD_CSI0_DAT18__IPU1_CSI0_DATA18    0x80000000
				MX6QDL_PAD_CSI0_DAT19__IPU1_CSI0_DATA19    0x80000000
				MX6QDL_PAD_CSI0_PIXCLK__IPU1_CSI0_PIXCLK   0x80000000
				MX6QDL_PAD_CSI0_MCLK__IPU1_CSI0_HSYNC      0x80000000
				MX6QDL_PAD_CSI0_VSYNC__IPU1_CSI0_VSYNC     0x80000000
			>;
		};
#endif
		pinctrl_ipu1_csi0: ipu1csi0grp {
			fsl,pins = <
				MX6QDL_PAD_CSI0_DAT12__IPU1_CSI0_DATA12    0x1b0b0
				MX6QDL_PAD_CSI0_DAT13__IPU1_CSI0_DATA13    0x1b0b0
				MX6QDL_PAD_CSI0_DAT14__IPU1_CSI0_DATA14    0x1b0b0
				MX6QDL_PAD_CSI0_DAT15__IPU1_CSI0_DATA15    0x1b0b0
				MX6QDL_PAD_CSI0_DAT16__IPU1_CSI0_DATA16    0x1b0b0
				MX6QDL_PAD_CSI0_DAT17__IPU1_CSI0_DATA17    0x1b0b0
				MX6QDL_PAD_CSI0_DAT18__IPU1_CSI0_DATA18    0x1b0b0
				MX6QDL_PAD_CSI0_DAT19__IPU1_CSI0_DATA19    0x1b0b0
				MX6QDL_PAD_CSI0_PIXCLK__IPU1_CSI0_PIXCLK   0x1b0b0
				MX6QDL_PAD_CSI0_MCLK__IPU1_CSI0_HSYNC      0x1b0b0
				MX6QDL_PAD_CSI0_VSYNC__IPU1_CSI0_VSYNC     0x1b0b0
			>;
		};

		pinctrl_ov5640: ov5640grp {
			fsl,pins = <
				MX6QDL_PAD_SD1_DAT2__GPIO1_IO19 0x1b0b0
				MX6QDL_PAD_SD1_CLK__GPIO1_IO20  0x1b0b0
			>;
		};

		pinctrl_ov5642: ov5642grp {
			fsl,pins = <
				MX6QDL_PAD_SD1_DAT0__GPIO1_IO16 0x1b0b0
				MX6QDL_PAD_SD1_DAT1__GPIO1_IO17 0x1b0b0
			>;
		};

		pinctrl_pcie: pciegrp {
			fsl,pins = <
				MX6QDL_PAD_GPIO_17__GPIO7_IO12		0x1b0b0	/* PCIE_RST_B */
				MX6QDL_PAD_CSI0_DATA_EN__GPIO5_IO20     0x1b0b0 /* PCIE_WAKE_B */
			>;
		};

		pinctrl_pwm1: pwm1grp {
			fsl,pins = <
				MX6QDL_PAD_NANDF_RB0__GPIO6_IO10	0x80000000 /* SMARC LCD_BKLT_EN */
				MX6QDL_PAD_GPIO_9__PWM1_OUT		0x1b0b1 /* SMARC LCD_BKLT_PWM */
			>;
		};

		pinctrl_sensors_reg: sensorsreggrp {
			fsl,pins = <
				MX6QDL_PAD_EIM_EB3__GPIO2_IO31		0x1b0b0
			>;
		};

		pinctrl_spdif: spdifgrp {
			fsl,pins = <	/* SMARC SPDIF_IN/OUT */
				MX6QDL_PAD_GPIO_16__SPDIF_IN            0x1b0b0
				MX6QDL_PAD_GPIO_19__SPDIF_OUT           0x1b0b0
			>;
		};

		pinctrl_uart1: uart1grp {
                       fsl,pins = <    /* SMARC SER0 */
				MX6QDL_PAD_SD3_DAT6__UART1_RX_DATA      0x1b0b1
				MX6QDL_PAD_SD3_DAT7__UART1_TX_DATA      0x1b0b1
				MX6QDL_PAD_EIM_D19__UART1_CTS_B         0x1b0b1
				MX6QDL_PAD_EIM_D20__UART1_RTS_B         0x1b0b1
			>;
		};

		pinctrl_uart2: uart2grp {
			fsl,pins = <    /* SMARC SER1 */
				MX6QDL_PAD_EIM_D26__UART2_TX_DATA       0x1b0b1
				MX6QDL_PAD_EIM_D27__UART2_RX_DATA       0x1b0b1
			>;
		};

		pinctrl_uart4: uart4grp {
			fsl,pins = <    /* SMARC SER3 */
				MX6QDL_PAD_KEY_COL0__UART4_TX_DATA      0x1b0b1
				MX6QDL_PAD_KEY_ROW0__UART4_RX_DATA      0x1b0b1
			>;
		};

		pinctrl_uart5: uart5grp {
			fsl,pins = <    /* SMARC SER2 */
				MX6QDL_PAD_KEY_COL1__UART5_TX_DATA	0x1b0b1
				MX6QDL_PAD_KEY_ROW1__UART5_RX_DATA	0x1b0b1
				MX6QDL_PAD_KEY_COL4__UART5_RTS_B	0x1b0b1
				MX6QDL_PAD_KEY_ROW4__UART5_CTS_B	0x1b0b1
			>;
		};

		pinctrl_usbotg: usbotggrp {
			fsl,pins = <	/* SMARC USB0 */
				MX6QDL_PAD_ENET_RX_ER__USB_OTG_ID	0x17059
			>;
		};

		pinctrl_usdhc1: usdhc1grp {
			fsl,pins = <    /* on-module eMMC */
				MX6QDL_PAD_SD1_CMD__SD1_CMD             0x17059
				MX6QDL_PAD_SD1_CLK__SD1_CLK             0x10059
				MX6QDL_PAD_SD1_DAT0__SD1_DATA0          0x17059
				MX6QDL_PAD_SD1_DAT1__SD1_DATA1          0x17059
				MX6QDL_PAD_SD1_DAT2__SD1_DATA2          0x17059
				MX6QDL_PAD_SD1_DAT3__SD1_DATA3          0x17059
				MX6QDL_PAD_NANDF_D0__SD1_DATA4          0x17059
				MX6QDL_PAD_NANDF_D1__SD1_DATA5          0x17059
				MX6QDL_PAD_NANDF_D2__SD1_DATA6          0x17059
				MX6QDL_PAD_NANDF_D3__SD1_DATA7          0x17059
			>;
		};

		pinctrl_usdhc2: usdhc2grp {
			fsl,pins = <	/* SMARC SDIO */
				MX6QDL_PAD_SD2_CMD__SD2_CMD		0x17059
				MX6QDL_PAD_SD2_CLK__SD2_CLK		0x10059
				MX6QDL_PAD_SD2_DAT0__SD2_DATA0		0x17059
				MX6QDL_PAD_SD2_DAT1__SD2_DATA1		0x17059
				MX6QDL_PAD_SD2_DAT2__SD2_DATA2		0x17059
				MX6QDL_PAD_SD2_DAT3__SD2_DATA3		0x17059
				//MX6QDL_PAD_GPIO_4__SD2_CD_B		0x80000000 /* controller internal CD doesn't work */
				MX6QDL_PAD_GPIO_4__GPIO1_IO04		0x80000000 /* SD2_CD_B: mux as GPIO instead */
				MX6QDL_PAD_GPIO_2__SD2_WP		0x80000000
			>;
		};

		pinctrl_usdhc4: usdhc4grp {
			fsl,pins = <	/* SMARC SDMMC */
				MX6QDL_PAD_SD4_CMD__SD4_CMD		0x17059
				MX6QDL_PAD_SD4_CLK__SD4_CLK		0x10059
				MX6QDL_PAD_SD4_DAT0__SD4_DATA0		0x17059
				MX6QDL_PAD_SD4_DAT1__SD4_DATA1		0x17059
				MX6QDL_PAD_SD4_DAT2__SD4_DATA2		0x17059
				MX6QDL_PAD_SD4_DAT3__SD4_DATA3		0x17059
				MX6QDL_PAD_SD4_DAT4__SD4_DATA4		0x17059
				MX6QDL_PAD_SD4_DAT5__SD4_DATA5		0x17059
				MX6QDL_PAD_SD4_DAT6__SD4_DATA6		0x17059
				MX6QDL_PAD_SD4_DAT7__SD4_DATA7		0x17059
				MX6QDL_PAD_NANDF_ALE__SD4_RESET		0x80000000
			>;
		};

		pinctrl_wdog: wdoggrp {
			fsl,pins = <
				MX6QDL_PAD_GPIO_1__WDOG2_B		0x1b0b0
			>;
		};
	};
};

&ldb {		/* LVDS (see fb above) */
	disp-power-on-supply = <&reg_smarc_lcd_vdd>; /* unsupported by driver */
	status = "okay";

	lvds-channel@0 {
		fsl,data-mapping = "spwg";	/* spwg or jeida (see chapter "Bit Mapping" in i.MX6 Reference Manual) */
		fsl,data-width = <24>;
		primary;
		status = "okay";

		display-timings {
			native-mode = <&timing0>;
			timing0: hsd100pxn1 {
				clock-frequency = <65000000>;
				hactive = <1024>;
				vactive = <600>;
				hback-porch = <220>;
				hfront-porch = <40>;
				vback-porch = <21>;
				vfront-porch = <7>;
				hsync-len = <60>;
				vsync-len = <10>;
			};
		};
	};
};

&pcie {
	pinctrl-names = "default";
	pinctrl-0 = <&pinctrl_pcie>;
	reset-gpio = <&gpio7 12 GPIO_ACTIVE_LOW>; /* PCIE_RST_B */
	/*Next line has no effect: half-implemented in older kernels, Freescale
	 * now removed code completely; gpio-key can serve as workaround. */
	wake-up-gpio = <&gpio5 20 GPIO_ACTIVE_LOW>; /* PCIE_WAKE_B */
	epdev_on-supply = <&vgen3_reg>;
	status = "okay";
};

&pwm1 {	/* SMARC LCD_BKLT_PWM */
	pinctrl-names = "default";
	pinctrl-0 = <&pinctrl_pwm1>;
	status = "okay";
};

&reg_arm {
       vin-supply = <&sw1a_reg>;
};

&reg_pu {
       vin-supply = <&sw1c_reg>;
};

&reg_soc {
       vin-supply = <&sw1c_reg>;
};

&reg_vdd1p1 {
	vin-supply = <&vgen5_reg>;
};

&reg_vdd2p5 {
	vin-supply = <&vgen5_reg>;
};

&snvs_poweroff {
	status = "okay";
};

&spdif {	/* SMARC SPDIF_IN/OUT */
	pinctrl-names = "default";
	pinctrl-0 = <&pinctrl_spdif>;
	assigned-clocks = <&clks IMX6QDL_CLK_SPDIF_SEL>, <&clks IMX6QDL_CLK_SPDIF_PODF>;
	assigned-clock-parents = <&clks IMX6QDL_CLK_PLL3_PFD3_454M>;
	assigned-clock-rates = <0>, <227368421>;
	status = "okay";
};

#if CONFIG_I2S_AUDIO
&ssi2 {	/* SMARC I2S0 (instead of SPI0) */
	status = "okay";
};
#endif

&uart1 {	/* SMARC SER0 */
	pinctrl-names = "default";
	pinctrl-0 = <&pinctrl_uart1>;
	fsl,uart-has-rtscts;
	status = "okay";
};

&uart2 {       /* SMARC SER1 */
	pinctrl-names = "default";
	pinctrl-0 = <&pinctrl_uart2>;
	status = "okay";
};

&uart4 {       /* SMARC SER3 */
	pinctrl-names = "default";
	pinctrl-0 = <&pinctrl_uart4>;
	status = "okay";
};

&uart5 {       /* SMARC SER2 */
	pinctrl-names = "default";
	pinctrl-0 = <&pinctrl_uart5>;
	fsl,uart-has-rtscts;
	status = "okay";
};

&usbh1 {	/* SMARC USB1,2 */
	vbus-supply = <&reg_smarc_usb2>; /* chained with usb1, see above */
	disable-over-current; /* connects to SMARC USB2_EN_OC# but not USB1_ */
	status = "okay";
};

&usbotg {	/* SMARC USB0 */
	vbus-supply = <&reg_smarc_usb0>;
	pinctrl-names = "default";
	pinctrl-0 = <&pinctrl_usbotg>;
	//dr_mode = "peripheral"; /* default is "otg", override with "host" or "peripheral" to set fixed role */
	disable-over-current;
	dr_mode = "otg";
	status = "okay";
};

&usdhc1 {	/* on-module eMMC */
	pinctrl-names = "default";
	pinctrl-0 = <&pinctrl_usdhc1>;
	bus-width = <8>;
	non-removable;
	status = "okay";
};

&usdhc2 {	/* SMARC SDIO */
	pinctrl-0 = <&pinctrl_usdhc2>;
	bus-width = <4>;
	//fsl,cd-controller; /* using controller internal CD doesn't work properly */
	cd-gpios = <&gpio1 4 GPIO_ACTIVE_LOW>; /* need to treat it as GPIO instead */
	fsl,wp-controller;
	vmmc-supply = <&reg_smarc_sdio_pwr>;
	vqmmc-supply = <&reg_smarc_sdio_pwr>;
	status = "okay";
};

&usdhc4 {	/* SMARC SDMMC */
	pinctrl-names = "default";
	pinctrl-0 = <&pinctrl_usdhc4>;
	bus-width = <8>;
	//non-removable; /* eMMC: no polling saves power */
	broken-cd; /* uSD slot on carrier: polling allows switching cards */
	no-1-8-v;
	auto-cmd23-broken;
	status = "okay";
};

&wdog1 {
	/* Contrary to other nodes Freescale's dtsi doesn't default to "disabled" here. */
	status = "disabled";
};

&wdog2 {
	/* This is the TrustZone watchdog, however pin mux leaves no other choice.
	 * We don't need an SoC reset (wdog_rst_b), but WDOG2_B --> system wide POR. */
	pinctrl-names = "default";
	pinctrl-0 = <&pinctrl_wdog>;
	fsl,ext-reset-output;
	status = "okay";
};

